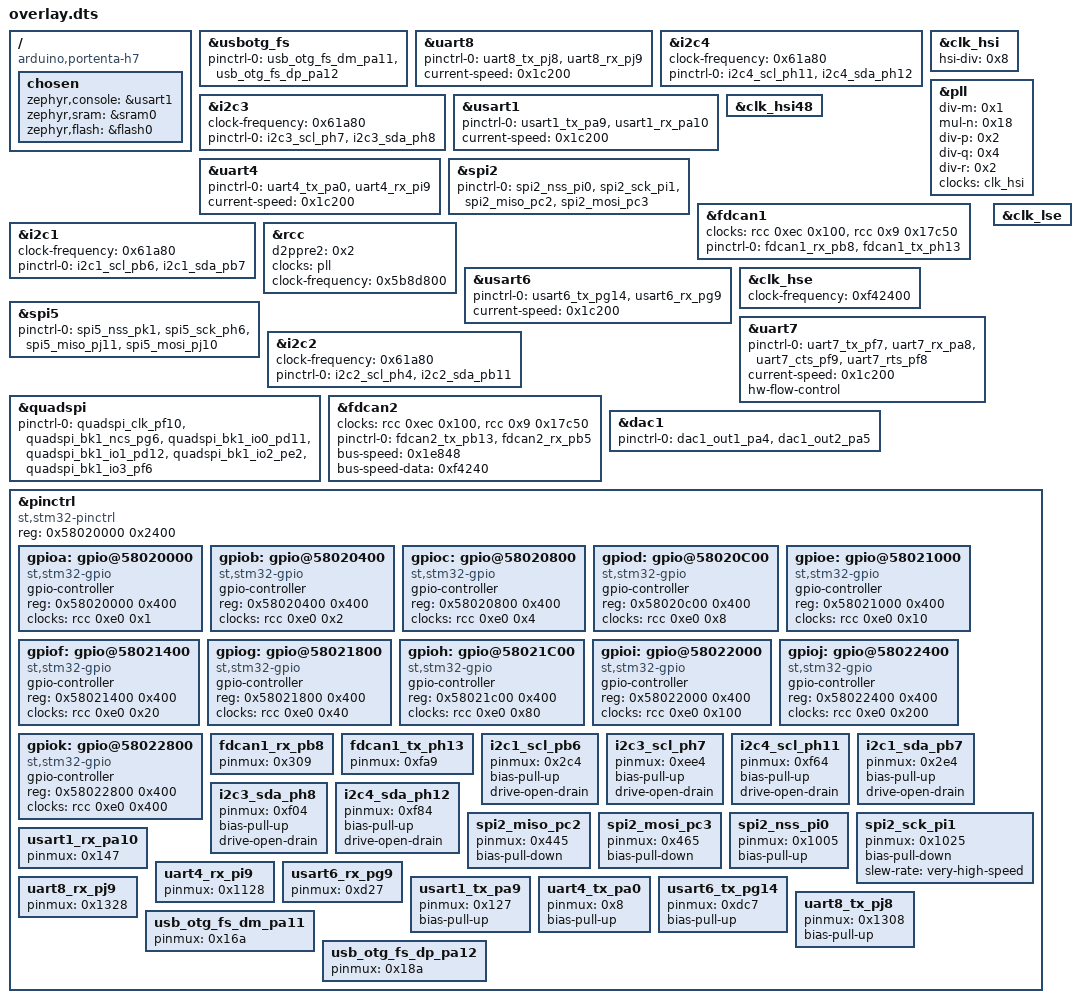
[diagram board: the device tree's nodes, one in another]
/ {
	compatible = "arduino,portenta-h7";
	chosen {
		zephyr,console = &usart1;
		zephyr,sram = &sram0;
		zephyr,flash = &flash0;
	};
};
&usbotg_fs{
	status = "okay";
	pinctrl-0 = < &usb_otg_fs_dm_pa11 &usb_otg_fs_dp_pa12 >;
	pinctrl-names = "default";
};
&uart8{
	pinctrl-0 = < &uart8_tx_pj8 &uart8_rx_pj9 >;
	pinctrl-names = "default";
	current-speed = < 0x1c200 >;
};
&i2c4{
	clock-frequency = < 0x61a80 >;
	pinctrl-0 = < &i2c4_scl_ph11 &i2c4_sda_ph12 >;
	pinctrl-names = "default";
};
&clk_hsi{
	status = "okay";
	hsi-div = < 0x8 >;
};
&i2c3{
	clock-frequency = < 0x61a80 >;
	pinctrl-0 = < &i2c3_scl_ph7 &i2c3_sda_ph8 >;
	pinctrl-names = "default";
};
&pll{
	status = "okay";
	div-m = < 0x1 >;
	mul-n = < 0x18 >;
	div-p = < 0x2 >;
	div-q = < 0x4 >;
	div-r = < 0x2 >;
	clocks = < &clk_hsi >;
};
&usart1{
	status = "okay";
	pinctrl-0 = < &usart1_tx_pa9 &usart1_rx_pa10 >;
	pinctrl-names = "default";
	current-speed = < 0x1c200 >;
};
&uart4{
	pinctrl-0 = < &uart4_tx_pa0 &uart4_rx_pi9 >;
	pinctrl-names = "default";
	current-speed = < 0x1c200 >;
};
&clk_hsi48{
	status = "okay";
};
&spi2{
	pinctrl-0 = < &spi2_nss_pi0 &spi2_sck_pi1 &spi2_miso_pc2 &spi2_mosi_pc3 >;
	pinctrl-names = "default";
};
&fdcan1{
	clocks = < &rcc 0xec 0x100 >, < &rcc 0x9 0x17c50 >;
	pinctrl-0 = < &fdcan1_rx_pb8 &fdcan1_tx_ph13 >;
	pinctrl-names = "default";
};
&i2c1{
	clock-frequency = < 0x61a80 >;
	status = "okay";
	pinctrl-0 = < &i2c1_scl_pb6 &i2c1_sda_pb7 >;
	pinctrl-names = "default";
};
&rcc{
	d2ppre2 = < 0x2 >;
	clocks = < &pll >;
	clock-frequency = < 0x5b8d800 >;
};
&usart6{
	pinctrl-0 = < &usart6_tx_pg14 &usart6_rx_pg9 >;
	pinctrl-names = "default";
	current-speed = < 0x1c200 >;
};
&clk_hse{
	status = "okay";
	clock-frequency = < 0xf42400 >;
};
&spi5{
	status = "okay";
	pinctrl-0 = < &spi5_nss_pk1 &spi5_sck_ph6 &spi5_miso_pj11 &spi5_mosi_pj10 >;
	pinctrl-names = "default";
};
&uart7{
	status = "okay";
	pinctrl-0 = < &uart7_tx_pf7 &uart7_rx_pa8 &uart7_cts_pf9 &uart7_rts_pf8 >;
	pinctrl-names = "default";
	current-speed = < 0x1c200 >;
	hw-flow-control;
};
&i2c2{
	clock-frequency = < 0x61a80 >;
	pinctrl-0 = < &i2c2_scl_ph4 &i2c2_sda_pb11 >;
	pinctrl-names = "default";
};
&quadspi{
	status = "okay";
	pinctrl-0 = < &quadspi_clk_pf10 &quadspi_bk1_ncs_pg6 &quadspi_bk1_io0_pd11 &quadspi_bk1_io1_pd12 &quadspi_bk1_io2_pe2 &quadspi_bk1_io3_pf6 >;
	pinctrl-names = "default";
};
&clk_lse{
	status = "okay";
};
&fdcan2{
	clocks = < &rcc 0xec 0x100 >, < &rcc 0x9 0x17c50 >;
	status = "okay";
	pinctrl-0 = < &fdcan2_tx_pb13 &fdcan2_rx_pb5 >;
	pinctrl-names = "default";
	bus-speed = < 0x1e848 >;
	bus-speed-data = < 0xf4240 >;
};
&dac1{
	status = "okay";
	pinctrl-0 = < &dac1_out1_pa4 &dac1_out2_pa5 >;
	pinctrl-names = "default";
};
&pinctrl{
	compatible = "st,stm32-pinctrl";
	#address-cells = < 0x1 >;
	#size-cells = < 0x1 >;
	reg = < 0x58020000 0x2400 >;
	gpioa: gpio@58020000 {
		compatible = "st,stm32-gpio";
		gpio-controller;
		#gpio-cells = < 0x2 >;
		reg = < 0x58020000 0x400 >;
		clocks = < &rcc 0xe0 0x1 >;
	};
	gpiob: gpio@58020400 {
		compatible = "st,stm32-gpio";
		gpio-controller;
		#gpio-cells = < 0x2 >;
		reg = < 0x58020400 0x400 >;
		clocks = < &rcc 0xe0 0x2 >;
	};
	gpioc: gpio@58020800 {
		compatible = "st,stm32-gpio";
		gpio-controller;
		#gpio-cells = < 0x2 >;
		reg = < 0x58020800 0x400 >;
		clocks = < &rcc 0xe0 0x4 >;
	};
	gpiod: gpio@58020C00 {
		compatible = "st,stm32-gpio";
		gpio-controller;
		#gpio-cells = < 0x2 >;
		reg = < 0x58020c00 0x400 >;
		clocks = < &rcc 0xe0 0x8 >;
	};
	gpioe: gpio@58021000 {
		compatible = "st,stm32-gpio";
		gpio-controller;
		#gpio-cells = < 0x2 >;
		reg = < 0x58021000 0x400 >;
		clocks = < &rcc 0xe0 0x10 >;
	};
	gpiof: gpio@58021400 {
		compatible = "st,stm32-gpio";
		gpio-controller;
		#gpio-cells = < 0x2 >;
		reg = < 0x58021400 0x400 >;
		clocks = < &rcc 0xe0 0x20 >;
	};
	gpiog: gpio@58021800 {
		compatible = "st,stm32-gpio";
		gpio-controller;
		#gpio-cells = < 0x2 >;
		reg = < 0x58021800 0x400 >;
		clocks = < &rcc 0xe0 0x40 >;
	};
	gpioh: gpio@58021C00 {
		compatible = "st,stm32-gpio";
		gpio-controller;
		#gpio-cells = < 0x2 >;
		reg = < 0x58021c00 0x400 >;
		clocks = < &rcc 0xe0 0x80 >;
	};
	gpioi: gpio@58022000 {
		compatible = "st,stm32-gpio";
		gpio-controller;
		#gpio-cells = < 0x2 >;
		reg = < 0x58022000 0x400 >;
		clocks = < &rcc 0xe0 0x100 >;
	};
	gpioj: gpio@58022400 {
		compatible = "st,stm32-gpio";
		gpio-controller;
		#gpio-cells = < 0x2 >;
		reg = < 0x58022400 0x400 >;
		clocks = < &rcc 0xe0 0x200 >;
	};
	gpiok: gpio@58022800 {
		compatible = "st,stm32-gpio";
		gpio-controller;
		#gpio-cells = < 0x2 >;
		reg = < 0x58022800 0x400 >;
		clocks = < &rcc 0xe0 0x400 >;
	};
	fdcan1_rx_pb8: fdcan1_rx_pb8 {
		pinmux = < 0x309 >;
	};
	fdcan1_tx_ph13: fdcan1_tx_ph13 {
		pinmux = < 0xfa9 >;
	};
	i2c1_scl_pb6: i2c1_scl_pb6 {
		pinmux = < 0x2c4 >;
		bias-pull-up;
		drive-open-drain;
	};
	i2c3_scl_ph7: i2c3_scl_ph7 {
		pinmux = < 0xee4 >;
		bias-pull-up;
		drive-open-drain;
	};
	i2c4_scl_ph11: i2c4_scl_ph11 {
		pinmux = < 0xf64 >;
		bias-pull-up;
		drive-open-drain;
	};
	i2c1_sda_pb7: i2c1_sda_pb7 {
		pinmux = < 0x2e4 >;
		bias-pull-up;
		drive-open-drain;
	};
	i2c3_sda_ph8: i2c3_sda_ph8 {
		pinmux = < 0xf04 >;
		bias-pull-up;
		drive-open-drain;
	};
	i2c4_sda_ph12: i2c4_sda_ph12 {
		pinmux = < 0xf84 >;
		bias-pull-up;
		drive-open-drain;
	};
	spi2_miso_pc2: spi2_miso_pc2 {
		pinmux = < 0x445 >;
		bias-pull-down;
	};
	spi2_mosi_pc3: spi2_mosi_pc3 {
		pinmux = < 0x465 >;
		bias-pull-down;
	};
	spi2_nss_pi0: spi2_nss_pi0 {
		pinmux = < 0x1005 >;
		bias-pull-up;
	};
	spi2_sck_pi1: spi2_sck_pi1 {
		pinmux = < 0x1025 >;
		bias-pull-down;
		slew-rate = "very-high-speed";
	};
	usart1_rx_pa10: usart1_rx_pa10 {
		pinmux = < 0x147 >;
	};
	uart4_rx_pi9: uart4_rx_pi9 {
		pinmux = < 0x1128 >;
	};
	usart6_rx_pg9: usart6_rx_pg9 {
		pinmux = < 0xd27 >;
	};
	uart8_rx_pj9: uart8_rx_pj9 {
		pinmux = < 0x1328 >;
	};
	usart1_tx_pa9: usart1_tx_pa9 {
		pinmux = < 0x127 >;
		bias-pull-up;
	};
	uart4_tx_pa0: uart4_tx_pa0 {
		pinmux = < 0x8 >;
		bias-pull-up;
	};
	usart6_tx_pg14: usart6_tx_pg14 {
		pinmux = < 0xdc7 >;
		bias-pull-up;
	};
	uart8_tx_pj8: uart8_tx_pj8 {
		pinmux = < 0x1308 >;
		bias-pull-up;
	};
	usb_otg_fs_dm_pa11: usb_otg_fs_dm_pa11 {
		pinmux = < 0x16a >;
	};
	usb_otg_fs_dp_pa12: usb_otg_fs_dp_pa12 {
		pinmux = < 0x18a >;
	};
};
